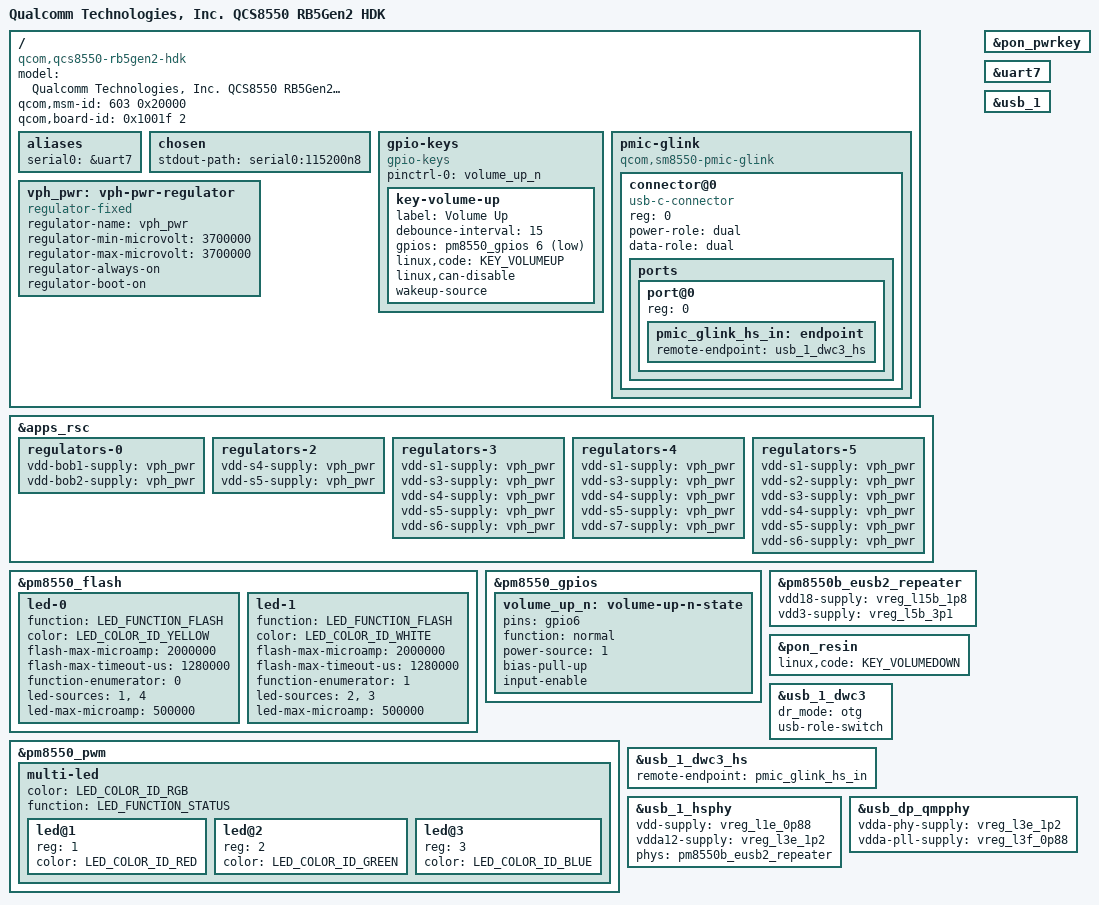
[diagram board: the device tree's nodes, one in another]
// SPDX-License-Identifier: BSD-3-Clause
/*
 * Copyright (c) 2024 Qualcomm Innovation Center, Inc. All rights reserved.
 */

/dts-v1/;

#include <dt-bindings/leds/common.h>
#include "qcs8550-rb5gen2.dtsi"
#include "pm8010.dtsi"
#include "pmr735d_a.dtsi"
#include "pmr735d_b.dtsi"

/ {
	model = "Qualcomm Technologies, Inc. QCS8550 RB5Gen2 HDK";
	compatible = "qcom,qcs8550-rb5gen2-hdk", "qcom,qcs8550-rb5gen2",
			"qcom,qcs8550", "qcom,qcm8550", "qcom,sm8550";

	qcom,msm-id = <603 0x20000>;
	qcom,board-id = <0x1001f 2>;

	aliases {
		serial0 = &uart7;
	};

	chosen {
		stdout-path = "serial0:115200n8";
	};

	gpio-keys {
		compatible = "gpio-keys";

		pinctrl-0 = <&volume_up_n>;
		pinctrl-names = "default";

		key-volume-up {
			label = "Volume Up";
			debounce-interval = <15>;
			gpios = <&pm8550_gpios 6 GPIO_ACTIVE_LOW>;
			linux,code = <KEY_VOLUMEUP>;
			linux,can-disable;
			wakeup-source;
		};
	};

	pmic-glink {
		compatible = "qcom,sm8550-pmic-glink", "qcom,pmic-glink";
		#address-cells = <1>;
		#size-cells = <0>;

		connector@0 {
			compatible = "usb-c-connector";
			reg = <0>;
			power-role = "dual";
			data-role = "dual";

			ports {
				#address-cells = <1>;
				#size-cells = <0>;

				port@0 {
					reg = <0>;

					pmic_glink_hs_in: endpoint {
						remote-endpoint = <&usb_1_dwc3_hs>;
					};
				};
			};
		};
	};

	vph_pwr: vph-pwr-regulator {
		compatible = "regulator-fixed";
		regulator-name = "vph_pwr";
		regulator-min-microvolt = <3700000>;
		regulator-max-microvolt = <3700000>;

		regulator-always-on;
		regulator-boot-on;
	};
};

&apps_rsc {
	regulators-0 {
		vdd-bob1-supply = <&vph_pwr>;
		vdd-bob2-supply = <&vph_pwr>;
	};

	regulators-2 {
		vdd-s4-supply = <&vph_pwr>;
		vdd-s5-supply = <&vph_pwr>;
	};

	regulators-3 {
		vdd-s1-supply = <&vph_pwr>;
		vdd-s3-supply = <&vph_pwr>;
		vdd-s4-supply = <&vph_pwr>;
		vdd-s5-supply = <&vph_pwr>;
		vdd-s6-supply = <&vph_pwr>;
	};

	regulators-4 {
		vdd-s1-supply = <&vph_pwr>;
		vdd-s3-supply = <&vph_pwr>;
		vdd-s4-supply = <&vph_pwr>;
		vdd-s5-supply = <&vph_pwr>;
		vdd-s7-supply = <&vph_pwr>;
	};

	regulators-5 {
		vdd-s1-supply = <&vph_pwr>;
		vdd-s2-supply = <&vph_pwr>;
		vdd-s3-supply = <&vph_pwr>;
		vdd-s4-supply = <&vph_pwr>;
		vdd-s5-supply = <&vph_pwr>;
		vdd-s6-supply = <&vph_pwr>;
	};
};

&pm8550_flash {
	status = "okay";

	led-0 {
		function = LED_FUNCTION_FLASH;
		color = <LED_COLOR_ID_YELLOW>;
		flash-max-microamp = <2000000>;
		flash-max-timeout-us = <1280000>;
		function-enumerator = <0>;
		led-sources = <1>, <4>;
		led-max-microamp = <500000>;
	};

	led-1 {
		function = LED_FUNCTION_FLASH;
		color = <LED_COLOR_ID_WHITE>;
		flash-max-microamp = <2000000>;
		flash-max-timeout-us = <1280000>;
		function-enumerator = <1>;
		led-sources = <2>, <3>;
		led-max-microamp = <500000>;
	};
};

&pm8550_gpios {
	volume_up_n: volume-up-n-state {
		pins = "gpio6";
		function = "normal";
		power-source = <1>;
		bias-pull-up;
		input-enable;
	};
};

&pm8550_pwm {
	status = "okay";

	multi-led {
		color = <LED_COLOR_ID_RGB>;
		function = LED_FUNCTION_STATUS;

		#address-cells = <1>;
		#size-cells = <0>;

		led@1 {
			reg = <1>;
			color = <LED_COLOR_ID_RED>;
		};

		led@2 {
			reg = <2>;
			color = <LED_COLOR_ID_GREEN>;
		};

		led@3 {
			reg = <3>;
			color = <LED_COLOR_ID_BLUE>;
		};
	};
};

&pm8550b_eusb2_repeater {
	vdd18-supply = <&vreg_l15b_1p8>;
	vdd3-supply = <&vreg_l5b_3p1>;
};

&pon_pwrkey {
	status = "okay";
};

&pon_resin {
	linux,code = <KEY_VOLUMEDOWN>;
	status = "okay";
};

&uart7 {
	status = "okay";
};

&usb_1 {
	status = "okay";
};

&usb_1_dwc3 {
	dr_mode = "otg";
	usb-role-switch;
};

&usb_1_dwc3_hs {
	remote-endpoint = <&pmic_glink_hs_in>;
};

&usb_1_hsphy {
	vdd-supply = <&vreg_l1e_0p88>;
	vdda12-supply = <&vreg_l3e_1p2>;

	phys = <&pm8550b_eusb2_repeater>;

	status = "okay";
};

&usb_dp_qmpphy {
	vdda-phy-supply = <&vreg_l3e_1p2>;
	vdda-pll-supply = <&vreg_l3f_0p88>;

	status = "okay";
};
